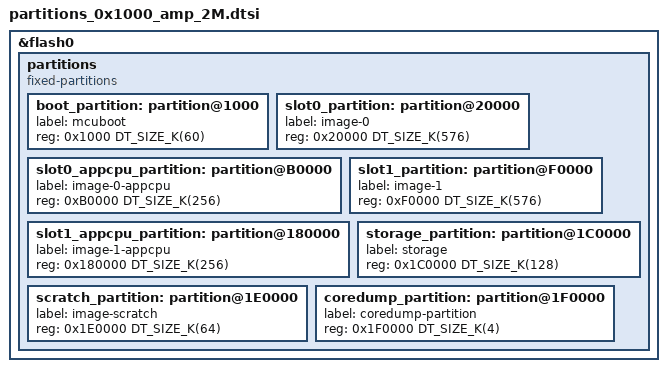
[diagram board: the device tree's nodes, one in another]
/*
 * Copyright (c) 2024 Espressif Systems (Shanghai) Co., Ltd.
 *
 * SPDX-License-Identifier: Apache-2.0
 */

 /* 2MB flash partition table */
&flash0 {
	partitions {
		compatible = "fixed-partitions";
		#address-cells = <1>;
		#size-cells = <1>;

		boot_partition: partition@1000 {
			label = "mcuboot";
			reg = <0x1000 DT_SIZE_K(60)>;
		};

		slot0_partition: partition@20000 {
			label = "image-0";
			reg = <0x20000 DT_SIZE_K(576)>;
		};

		slot0_appcpu_partition: partition@B0000 {
			label = "image-0-appcpu";
			reg = <0xB0000 DT_SIZE_K(256)>;
		};

		slot1_partition: partition@F0000 {
			label = "image-1";
			reg = <0xF0000 DT_SIZE_K(576)>;
		};

		slot1_appcpu_partition: partition@180000 {
			label = "image-1-appcpu";
			reg = <0x180000 DT_SIZE_K(256)>;
		};

		storage_partition: partition@1C0000 {
			label = "storage";
			reg = <0x1C0000 DT_SIZE_K(128)>;
		};

		scratch_partition: partition@1E0000 {
			label = "image-scratch";
			reg = <0x1E0000 DT_SIZE_K(64)>;
		};

		coredump_partition: partition@1F0000 {
			label = "coredump-partition";
			reg = <0x1F0000 DT_SIZE_K(4)>;
		};
	};
};
